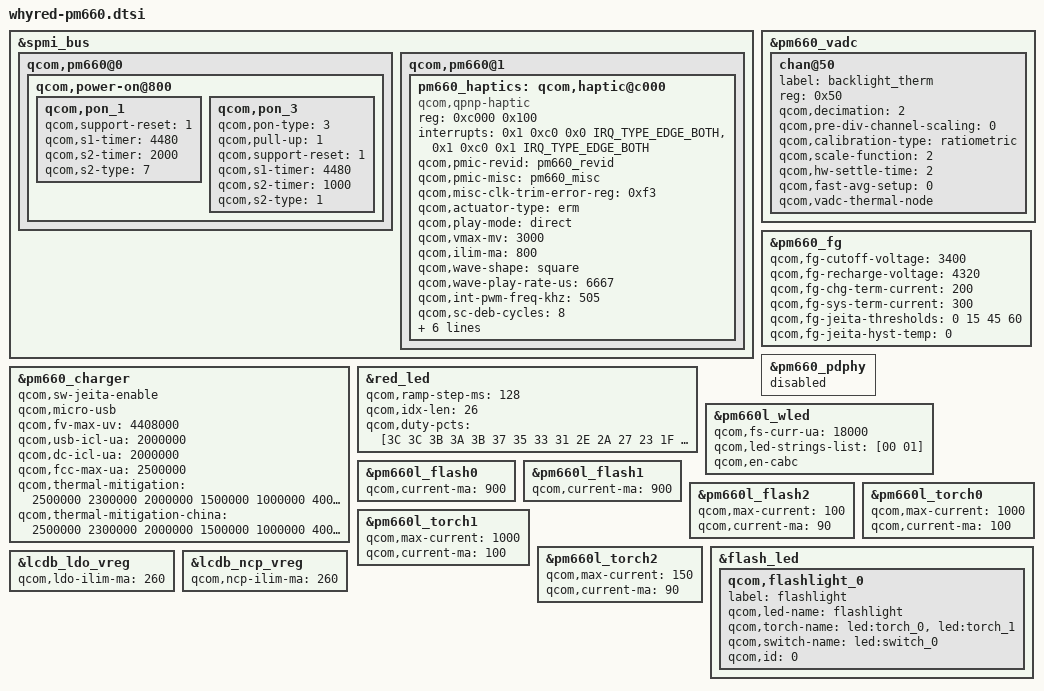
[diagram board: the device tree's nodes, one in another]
/*  msm-pm660.dtsi */
&spmi_bus {
	qcom,pm660@0 {
		qcom,power-on@800 {
			qcom,pon_1 {
				qcom,support-reset = <1>;
				qcom,s1-timer = <4480>;
				qcom,s2-timer = <2000>;
				qcom,s2-type = <7>;
			};

			qcom,pon_3 {
				qcom,pon-type = <3>;
				qcom,pull-up = <1>;
				qcom,support-reset = <1>;
				qcom,s1-timer = <4480>;
				qcom,s2-timer = <1000>;
				qcom,s2-type = <1>;
			};
		};
	};
};

&pm660_vadc {
	chan@50 {
		label = "backlight_therm";
		reg = <0x50>;
		qcom,decimation = <2>;
		qcom,pre-div-channel-scaling = <0>;
		qcom,calibration-type = "ratiometric";
		qcom,scale-function = <2>;
		qcom,hw-settle-time = <2>;
		qcom,fast-avg-setup = <0>;
		qcom,vadc-thermal-node;
	};
};

&pm660_charger {
	qcom,sw-jeita-enable;
	qcom,micro-usb;
	qcom,fv-max-uv  = <4408000>;
	qcom,usb-icl-ua = <2000000>;
	qcom,dc-icl-ua = <2000000>;
	qcom,fcc-max-ua = <2500000>;
	qcom,thermal-mitigation
			= <2500000 2300000 2000000 1500000 1000000 400000 200000>;
	qcom,thermal-mitigation-china
			= <2500000 2300000 2000000 1500000 1000000 400000 200000>;
};

&pm660_fg {
	qcom,fg-cutoff-voltage = <3400>;
	qcom,fg-recharge-voltage = <4320>;
	qcom,fg-chg-term-current = <200>;
	qcom,fg-sys-term-current = <300>;
	qcom,fg-jeita-thresholds = <0 15 45 60>;
	qcom,fg-jeita-hyst-temp = <0>;
};

&pm660_pdphy {
	status = "disabled";
};

&spmi_bus {
	qcom,pm660@1 {
		/delete-node/ qcom,haptics@c000;
		pm660_haptics: qcom,haptic@c000 {
			compatible = "qcom,qpnp-haptic";
			reg = <0xc000 0x100>;
			interrupts = <0x1 0xc0 0x0 IRQ_TYPE_EDGE_BOTH>,
					<0x1 0xc0 0x1 IRQ_TYPE_EDGE_BOTH>;
			interrupt-names = "sc-irq", "play-irq";
			qcom,pmic-revid = <&pm660_revid>;
			qcom,pmic-misc = <&pm660_misc>;
			qcom,misc-clk-trim-error-reg = <0xf3>;
			qcom,actuator-type = "erm";
			qcom,play-mode = "direct";
			qcom,vmax-mv = <3000>;
			qcom,ilim-ma = <800>;
			qcom,wave-shape = "square";
			qcom,wave-play-rate-us = <6667>;
			qcom,int-pwm-freq-khz = <505>;
			qcom,sc-deb-cycles = <8>;
			qcom,en-brake;
			qcom,brake-pattern = [03 03 00 00];
			qcom,lra-high-z = "opt0";
			qcom,lra-auto-res-mode = "qwd";
			qcom,lra-calibrate-at-eop = <0>;
			qcom,correct-lra-drive-freq;
		};
	};
};

/* msm-pm660l.dtsi */
&red_led {
	qcom,ramp-step-ms = <128>;
	qcom,idx-len = <26>;
	qcom,duty-pcts =
		[3C 3C 3B 3A 3B 37 35 33 31 2E 2A 27 23
		1F 1B 17 13 0E 09 05 00 00 00 00 00 00];
};

&pm660l_wled {
	/delete-property/ qcom,auto-calibration-enable;
	qcom,fs-curr-ua = <18000>;
	qcom,led-strings-list = [00 01];
	qcom,en-cabc;
};

&pm660l_flash0 {
	qcom,current-ma = <900>;
};

&pm660l_flash1{
	qcom,current-ma = <900>;
};

&pm660l_flash2 {
	qcom,max-current = <100>;
	qcom,current-ma = <90>;
};

&pm660l_torch0 {
	qcom,max-current = <1000>;
	qcom,current-ma = <100>;
};

&pm660l_torch1 {
	qcom,max-current = <1000>;
	qcom,current-ma = <100>;
};

&pm660l_torch2 {
	qcom,max-current = <150>;
	qcom,current-ma = <90>;
};

&flash_led {
	qcom,flashlight_0 {
		label = "flashlight";
		qcom,led-name = "flashlight";
		qcom,torch-name = "led:torch_0", "led:torch_1";
		qcom,switch-name = "led:switch_0";
		qcom,id = <0>;
	};
};

&lcdb_ldo_vreg {
	qcom,ldo-ilim-ma = <260>;
};

&lcdb_ncp_vreg {
	qcom,ncp-ilim-ma = <260>;
};
